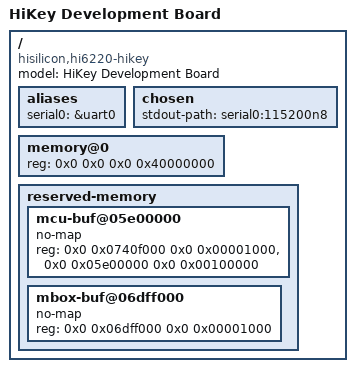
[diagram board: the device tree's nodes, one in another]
/*
 * dts file for Hisilicon HiKey Development Board
 *
 * Copyright (C) 2015, Hisilicon Ltd.
 *
 */

/dts-v1/;

#include "hi6220.dtsi"

/ {
	model = "HiKey Development Board";
	compatible = "hisilicon,hi6220-hikey", "hisilicon,hi6220";

	aliases {
		serial0 = &uart0;
	};

	chosen {
		stdout-path = "serial0:115200n8";
	};

	memory@0 {
		device_type = "memory";
		reg = <0x0 0x0 0x0 0x40000000>;
	};

	reserved-memory {
		#address-cells = <2>;
		#size-cells = <2>;
		ranges;

		mcu-buf@05e00000 {
			no-map;
			reg = <0x0 0x0740f000 0x0 0x00001000>,	/* MCU firmware section */
			      <0x0 0x05e00000 0x0 0x00100000>;	/* MCU firmware buffer */
		};

		mbox-buf@06dff000 {
			no-map;
			reg = <0x0 0x06dff000 0x0 0x00001000>;	/* Mailbox message buf */
		};
	};
};
